# cslr_memprot_L1D register map
Vendor: Texas Instruments
Peripheral module from a debugger description file (folder TCI6484_C6457).
Registers are 32-bit, access not given, reset 0xFF36 unless marked. A register's access mark holds for its fields unless they carry their own. Offsets are as the file gives them; lines under a group give offsets from that group; [hi:lo] are bit positions; {n}, {i} and the like mark numbered series; 'fields as' and 'values as' point back to an identical list; <NAME> marks a mode.

## MEMPROTL1D — Memory Protection for L1D
0x00 MPFAR rw reset 0x0 — L1D Memory Protection Fault Address Reg
  [31:0] ADDR — L1D Fault Address
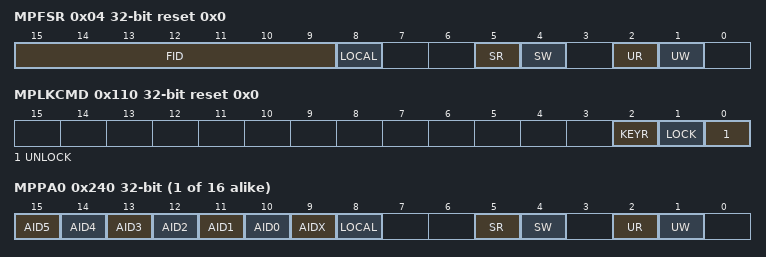
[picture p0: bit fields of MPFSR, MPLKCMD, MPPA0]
0x04 MPFSR reset 0x0 — L1D Memory Protection Fault Status Reg
  [15:9] FID ro — Bit 6:0 of faulting requestor. If ID is narrower than 7 bits, the remaining bits return 0. If ID is wider than 7 bits, the additional bits get truncated. FID = 0 if LOCAL = 1.
  [8] LOCAL ro — 0 - Normal operation. 1- Access was a "LOCAL" access.
  [5] SR ro — Superviser read access type
    1=READ; 0=NORMAL
  [4] SW ro — Superviser write access type
    1=WRITE; 0=NORMAL
  [2] UR ro — User read access type
    1=READ; 0=NORMAL
  [1] UW ro — User write access type
    1=WRITE; 0=NORMAL
0x08 MPFCLR reset 0x0 — L1D Memory Fault Clear Register
  [0] MPFCLR wo — Set to clear fault
    1=CLEAR (Clears Fault)
0x100 MPLK0 wo reset 0x0 — L1D Memory Protection Lock Key bits 31:0
  [31:0] LOCKBIT0TO31
0x104 MPLK1 wo reset 0x0 — L1D Memory Protection Lock Key bits 63:32
  [31:0] LOCKBIT32TO63
0x108 MPLK2 reset 0x0 — L1D Memory Protection Lock Key bits 95:64
  [31:0] Reserved — (access N)
0x10C MPLK3 reset 0x0 — L1D Memory Protection Lock Key bits 127:96
  [31:0] Reserved — (access N)
0x110 MPLKCMD reset 0x0 — L1D Memory Protection Lock Key Command Register
  [2] KEYR wo — Interface to initiate a lock/unlock sequence
    1=YES (Indicates the lock\unlock sequence and resets any state associated with the lock\unlock sequence); 0=NO (No effect)
  [1] LOCK wo — Interface to complete a lock sequence
    1=YES (Locks the lock provided that the software executed the sequence correctly); 0=NO (No effect)
  [0] UNLOCK wo — Interface to complete a unlock sequence
    1=YES (Unlocks the lock provided that the software executed the sequence correctly); 0=NO (No effect)
0x114 MPLKSTAT reset 0x0 — L1D Memory Protection Lock Key Status Register
  [0] LK ro — Indicates the lock's current status.
    1=ENGAGED (Lock is engaged); 0=DISENGAGED (Lock is not engaged)
{0x240+4i} MPPA{i} (i=0..15) — L1D Memory Protection Page Attribute Register
  [15] AID5 rw — Controls access from ID = 5.
    0=NO (Access denied.); 1=YES (Access granted.)
  [14] AID4 rw — Controls access from ID = 4.
    0=NO (Access denied.); 1=YES (Access granted.)
  [13] AID3 rw — Controls access from ID = 3.
    0=NO (Access denied.); 1=YES (Access granted.)
  [12] AID2 rw — Controls access from ID =2.
    0=NO (Access denied.); 1=YES (Access granted.)
  [11] AID1 rw — Controls access from ID = 1.
    0=NO (Access denied.); 1=YES (Access granted.)
  [10] AID0 rw — Controls access from ID = 0.
    0=NO (Access denied.); 1=YES (Access granted.)
  [9] AIDX rw — Controls ID >=6.
    0=NO (Access denied.); 1=YES (Access granted.)
  [8] LOCAL rw — Controls access from CPU to local memories (L1/L2).
    0=NO (Access denied.); 1=YES (Access granted.)
  [5] SR — Supervisor read access type.
    0=NO (Normal operation); 1=YES (Indicates a Supervisor read request.)
  [4] SW — Supervisor write access type.
    0=NO (Normal operation); 1=YES (Indicates a Supervisor write request.)
  [2] UR rw — User read access type.
    0=NO (Normal operation); 1=YES (Indicates a user read request.)
  [1] UW rw — User write access type.
    0=NO (Normal operation); 1=YES (Indicates a user write request.)
